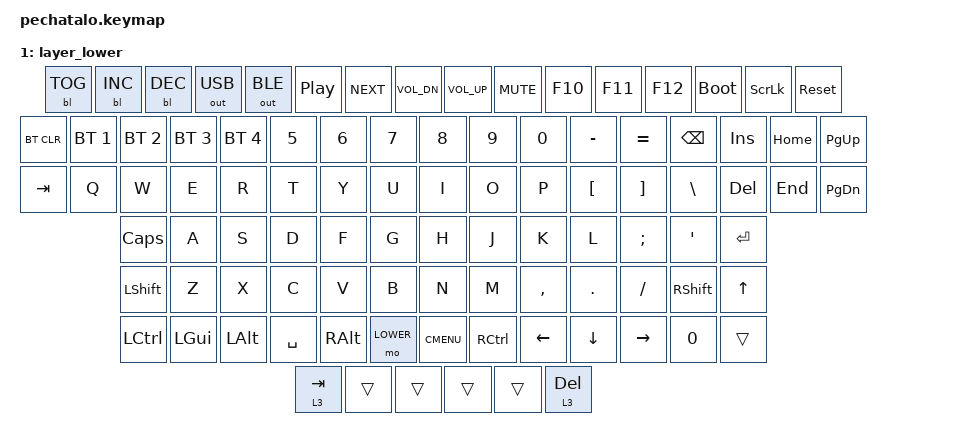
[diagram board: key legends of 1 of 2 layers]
/*
 * Copyright (c) 2021 Nick Winans
 *
 * SPDX-License-Identifier: MIT
 */

#include <behaviors.dtsi>
#include <dt-bindings/zmk/keys.h>
#include <dt-bindings/zmk/backlight.h>
#include <dt-bindings/zmk/bt.h>
#include <dt-bindings/zmk/outputs.h>

#define DEFAULT 0
#define LOWER   1


/ {
	keymap {
		compatible = "zmk,keymap";
		
		default_layer {
// ---------------------------------------------------------------------------------------------------------------
// | ESC |     | F1  | F2  | F3  |  F4 |  | F5  | F6  | F7  | F8  |  | F9  | F10 | F11 | F12|  | PS  | SL  | PB  |
// |  ~  |  1  |  2  |  3  |  4  |  5  |  6  |  7  |  8  |  9  |  0  |  -  |  =  |   BKSP   |  | INS | HM  | PUP |
// | TAB  |  Q  |  W  |  E  |  R  |  T  |  Y  |  U  |  I  |  O  |  P  |  [  |  ]  |   "|"   |  | DEL | END | PDN |
// | CAPS  |  A  |  S  |  D  |  F  |  G  |  H  |  J  |  K  |  L  |  ;  |  '  |     ENTER    |		             |
// |  SHIFT  |  Z  |  X  |  C  |  V  |  B  |  N  |  M  |  ,  |  .  |  /  |      SHIFT       |	     | UP  |     |
// |  CTL  |  WIN  |  ALT  |            SPACE              |  ALT  |  FN   |  MO(1) |  CTL  |  | LFT | DWN | RGHT|
// ---------------------------------------------------------------------------------------------------------------
			bindings = <
	&kp ESC  &kp F1  &kp F2  &kp F3  &kp F4    &kp F5  &kp F6  &kp F7  &kp F8    &kp F9  &kp F10  &kp F11  &kp F12    &kp PSCRN  &kp SLCK  &kp PAUSE_BREAK
	&kp GRAVE &kp N1 &kp N2 &kp N3 &kp N4 &kp N5 &kp N6 &kp N7 &kp N8 &kp N9 &kp N0 &kp MINUS &kp EQUAL  &kp BSPC        &kp INS    &kp HOME  &kp PG_UP
	&kp TAB  &kp Q  &kp W  &kp E  &kp R  &kp T  &kp Y  &kp U  &kp I  &kp O  &kp P  &kp LBKT  &kp RBKT  &kp BSLH	&kp DEL    &kp END   &kp PG_DN
	&kp CLCK  &kp A  &kp S  &kp D  &kp F  &kp G  &kp H  &kp J  &kp K  &kp L  &kp SEMI &kp SQT           &kp RET
	&kp LSHFT   &kp Z  &kp X  &kp C  &kp V  &kp B  &kp N  &kp M  &kp COMMA &kp DOT &kp FSLH           &kp RSHFT		   &kp UP
	&kp LCTRL &kp LGUI &kp LALT             &kp SPACE                     &kp RIGHT_ALT  &mo LOWER  &kp K_CMENU  &kp RCTRL	&kp LEFT  &kp DOWN  &kp RIGHT
			>;
		};

		 layer_lower {
            bindings = <
 	&bl BL_TOG  &bl BL_INC  &bl BL_DEC  &out OUT_USB  &out OUT_BLE    &kp C_PP  &kp C_NEXT  &kp C_VOL_DN  &kp C_VOL_UP    &kp C_MUTE  &kp F10  &kp F11  &kp F12  &bootloader  &kp SLCK &sys_reset 
	&bt BT_CLR &bt BT_SEL 1 &bt BT_SEL 2 &bt BT_SEL 3 &bt BT_SEL 4 &kp N5 &kp N6 &kp N7 &kp N8 &kp N9 &kp N0 &kp MINUS &kp EQUAL  &kp BSPC        &kp INS    &kp HOME  &kp PG_UP
	&kp TAB  &kp Q  &kp W  &kp E  &kp R  &kp T  &kp Y  &kp U  &kp I  &kp O  &kp P  &kp LBKT  &kp RBKT  &kp BSLH	&kp DEL    &kp END   &kp PG_DN
	&kp CLCK  &kp A  &kp S  &kp D  &kp F  &kp G  &kp H  &kp J  &kp K  &kp L  &kp SEMI &kp SQT           &kp RET
	&kp LSHFT   &kp Z  &kp X  &kp C  &kp V  &kp B  &kp N  &kp M  &kp COMMA &kp DOT &kp FSLH           &kp RSHFT		   &kp UP
	&kp LCTRL &kp LGUI &kp LALT             &kp SPACE                     &kp RIGHT_ALT  &mo LOWER  &kp K_CMENU  &kp RCTRL	&kp LEFT  &kp DOWN  &kp RIGHT&kp N0           &trans
                                           &lt 3 TAB    &trans     &trans     &trans    &trans  &lt 3 DEL
            >;
        };
	};
};
